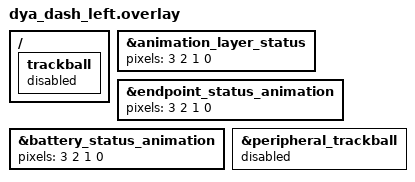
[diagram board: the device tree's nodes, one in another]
#include "dya_dash.dtsi"

/ {
    trackball: trackball {
        status = "disabled";
    };
};

&animation_layer_status {
    pixels = <3 2 1 0>;
};

&endpoint_status_animation {
    pixels = <3 2 1 0>;
};

&battery_status_animation {
    pixels = <3 2 1 0>;
};

&peripheral_trackball {
    status = "disabled"; // enabled by snippet
};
